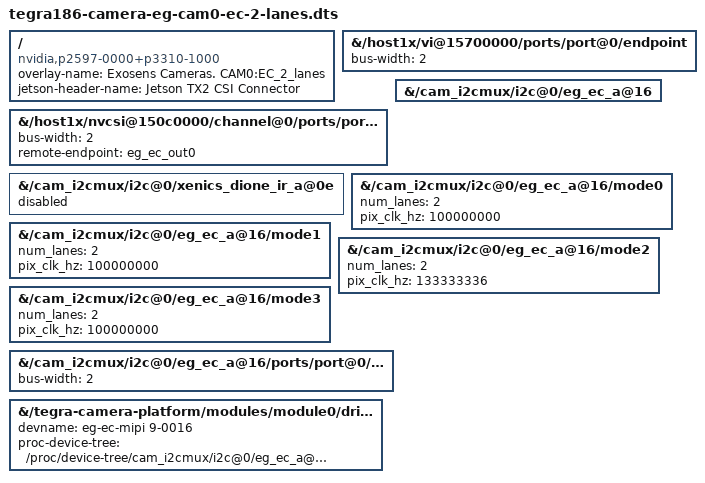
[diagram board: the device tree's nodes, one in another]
// SPDX-License-Identifier: GPL-2.0-only
// SPDX-FileCopyrightText: Copyright (c) 2025, Exosens. All rights reserved.

/dts-v1/;
/plugin/;

/ {
	overlay-name = "Exosens Cameras. CAM0:EC_2_lanes";
	jetson-header-name = "Jetson TX2 CSI Connector";
	compatible = "nvidia,p2597-0000+p3310-1000",
	             "nvidia,p2597-0000+p3489-0000",
	             "nvidia,p2597-0000+p3489-0888",
	             "nvidia,p3509-0000+p3636-0001";

	fragment@10 {
		target-path = "/host1x/vi@15700000/ports/port@0/endpoint";
		__overlay__ {
			bus-width = <2>;
		};
	};

	fragment@11 {
		target-path = "/host1x/nvcsi@150c0000/channel@0/ports/port@0/endpoint@0";
		__overlay__ {
			bus-width = <2>;
			remote-endpoint = <&eg_ec_out0>;
		};
	};

	/* Disable Dione */
	fragment@12 {
		target-path = "/cam_i2cmux/i2c@0/xenics_dione_ir_a@0e";
		__overlay__ {
			status = "disabled";
		};
	};

	/* Enable EC */
	fragment@13 {
		target-path = "/cam_i2cmux/i2c@0/eg_ec_a@16";
		__overlay__ {
			status = "okay";
		};
	};
	fragment@15 {
		target-path = "/cam_i2cmux/i2c@0/eg_ec_a@16/mode0";
		__overlay__ {
			num_lanes = "2";
			pix_clk_hz = "100000000";
		};
	};
	fragment@16 {
		target-path = "/cam_i2cmux/i2c@0/eg_ec_a@16/mode1";
		__overlay__ {
			num_lanes = "2";
			pix_clk_hz = "100000000";
		};
	};
	fragment@18 {
		target-path = "/cam_i2cmux/i2c@0/eg_ec_a@16/mode2";
		__overlay__ {
			num_lanes = "2";
			pix_clk_hz = "133333336";
		};
	};
	fragment@19 {
		target-path = "/cam_i2cmux/i2c@0/eg_ec_a@16/mode3";
		__overlay__ {
			num_lanes = "2";
			pix_clk_hz = "100000000";
		};
	};
	fragment@20 {
		target-path = "/cam_i2cmux/i2c@0/eg_ec_a@16/ports/port@0/endpoint";
		__overlay__ {
			bus-width = <2>;
		};
	};

	fragment@21 {
		target-path = "/tegra-camera-platform/modules/module0/drivernode0";
		__overlay__ {
			devname = "eg-ec-mipi 9-0016";
			proc-device-tree = "/proc/device-tree/cam_i2cmux/i2c@0/eg_ec_a@16";
		};
	};
};
